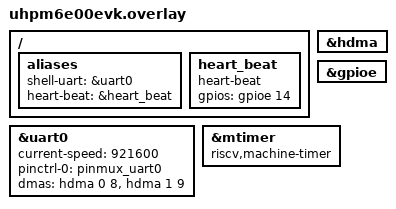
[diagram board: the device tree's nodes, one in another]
#include <dt-bindings/gpio/gpio.h>

/ {
	aliases {
		shell-uart = &uart0;
		heart-beat = &heart_beat;
	};

	heart_beat: heart_beat {
		compatible = "heart-beat";
		gpios = <&gpioe 14 GPIO_ACTIVE_HIGH>;
	};
};

&uart0 {
	status = "okay";
	current-speed = <921600>;
	pinctrl-0 = <&pinmux_uart0>;
	pinctrl-names = "default";
	dmas = <&hdma 0 8>, <&hdma 1 9>;
	dma-names = "rx", "tx";
};

&hdma {
	status = "okay";
};

&gpioe {
	status = "okay";
};

&mtimer {
	compatible = "riscv,machine-timer", "andestech,machine-timer";
	reg-names = "mtime", "mtimecmp";
};
